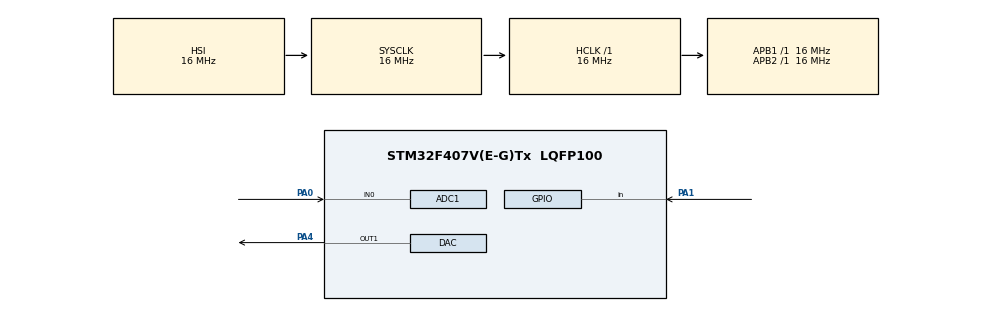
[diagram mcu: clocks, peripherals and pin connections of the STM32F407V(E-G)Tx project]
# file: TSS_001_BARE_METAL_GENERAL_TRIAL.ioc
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Mcu.Family=STM32F4
SH.COMP_DAC1_group.0=DAC_OUT1,DAC_OUT1
Dma.ADC1.0.Instance=DMA2_Stream0
RCC.CortexFreq_Value=16000000
ADC1.Rank-0\#ChannelRegularConversion=1
ADC1.ContinuousConvMode=ENABLE
Dma.DAC1.1.PeriphInc=DMA_PINC_DISABLE
ProjectManager.StackSize=0x400
PA0-WKUP.Signal=ADCx_IN0
Dma.DAC1.1.MemInc=DMA_MINC_ENABLE
Dma.ADC1.0.PeriphDataAlignment=DMA_PDATAALIGN_BYTE
Dma.DAC1.1.Mode=DMA_CIRCULAR
ProjectManager.TargetToolchain=STM32CubeIDE
NVIC.DMA1_Stream5_IRQn=true\:0\:0\:false\:false\:true\:false\:true
Dma.ADC1.0.Mode=DMA_CIRCULAR
ADC1.Resolution=ADC_RESOLUTION_8B
Dma.ADC1.0.Priority=DMA_PRIORITY_LOW
Dma.ADC1.0.Direction=DMA_PERIPH_TO_MEMORY
NVIC.DMA2_Stream0_IRQn=true\:0\:0\:false\:false\:true\:false\:true
RCC.LSE_VALUE=32768
Dma.ADC1.0.MemDataAlignment=DMA_MDATAALIGN_BYTE
PA1.Signal=GPIO_Input
RCC.AHBFreq_Value=16000000
ADC1.Channel-0\#ChannelRegularConversion=ADC_CHANNEL_0
RCC.HSE_VALUE=25000000
ADC1.ScanConvMode=DISABLE
board=custom
RCC.VCOOutputFreq_Value=192000000
RCC.APB2Freq_Value=16000000
Dma.ADC1.0.PeriphInc=DMA_PINC_DISABLE
Dma.DAC1.1.PeriphDataAlignment=DMA_PDATAALIGN_HALFWORD
SH.ADCx_IN0.0=ADC1_IN0,IN0
Dma.DAC1.1.Priority=DMA_PRIORITY_LOW
ADC1.DMAContinuousRequests=ENABLE
Dma.DAC1.1.FIFOMode=DMA_FIFOMODE_DISABLE
Mcu.Name=STM32F407V(E-G)Tx
ADC1.SamplingTime-0\#ChannelRegularConversion=ADC_SAMPLETIME_480CYCLES
Dma.DAC1.1.Direction=DMA_MEMORY_TO_PERIPH
PA4.Signal=COMP_DAC1_group
RCC.SYSCLKFreq_VALUE=16000000
Mcu.Package=LQFP100
ADC1.master=1
Dma.DAC1.1.Instance=DMA1_Stream5
Dma.ADC1.0.MemInc=DMA_MINC_ENABLE
ProjectManager.HeapSize=0x200
RCC.HSI_VALUE=16000000
NVIC.PriorityGroup=NVIC_PRIORITYGROUP_4
ADC1.NbrOfConversionFlag=1
Dma.Request1=DAC1
Dma.ADC1.0.FIFOMode=DMA_FIFOMODE_DISABLE
RCC.APB1Freq_Value=16000000
Dma.Request0=ADC1
Dma.DAC1.1.MemDataAlignment=DMA_MDATAALIGN_HALFWORD

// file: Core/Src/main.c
/* USER CODE BEGIN Header */
/**
  ******************************************************************************
  * @file           : main.c
  * @brief          : Main program body
  ******************************************************************************
  * @attention
  *
  * <h2><center>&copy; Copyright (c) 2022 STMicroelectronics.
  * All rights reserved.</center></h2>
  *
  * This software component is licensed by ST under BSD 3-Clause license,
  * the "License"; You may not use this file except in compliance with the
  * License. You may obtain a copy of the License at:
  *                        opensource.org/licenses/BSD-3-Clause
  *
  ******************************************************************************
  */
/* USER CODE END Header */
#include "main.h"

ADC_HandleTypeDef hadc1;
DMA_HandleTypeDef hdma_adc1;

DAC_HandleTypeDef hdac;
DMA_HandleTypeDef hdma_dac1;

void SystemClock_Config(void);
static void MX_GPIO_Init(void);
static void MX_DMA_Init(void);
static void MX_ADC1_Init(void);
static void MX_DAC_Init(void);

/* USER CODE BEGIN 0 */
uint8_t ButtonCount = 0 ;
uint8_t AdcValue8Bits ;

/*__weak void HAL_ADC_ConvHalfCpltCallback(ADC_HandleTypeDef* hadc) */

/**
  * ADC and DAC - DMA SETTINGS
  * DMA REQUEST SETTINGS :
  * MODE -> CIRCULAR MODE
  * DATA WIDTH   -> BYTE
  * BYTE         -> 8-BIT
  * HALF WORD    -> 16-BIT
  * WORD         -> 32-BIT
  * DOUBLE WORD  -> 64-BIT
  */

/* USER CODE END 0 */

int main(void)
{

  /* MCU Configuration--------------------------------------------------------*/

  /* Reset of all peripherals, Initializes the Flash interface and the Systick. */
  HAL_Init();

  /* Configure the system clock */
  SystemClock_Config();

  /* Initialize all configured peripherals */
  MX_GPIO_Init();
  MX_DMA_Init();
  MX_ADC1_Init();
  MX_DAC_Init();
  /* USER CODE BEGIN 2 */
  HAL_ADC_Start_DMA(&hadc1, (uint32_t *)&AdcValue8Bits, 1);
  HAL_DAC_Start_DMA(&hdac, DAC_CHANNEL_1, (uint32_t *)&AdcValue8Bits, 1, DAC_ALIGN_8B_R);
  /* USER CODE END 2 */

  /* Infinite loop */
  while (1)
  {

    /* USER CODE BEGIN 3 */
	  if(HAL_GPIO_ReadPin(GPIOA, GPIO_PIN_1))
	  {
		  while(HAL_GPIO_ReadPin(GPIOA, GPIO_PIN_1));
		  HAL_Delay(50);
		  ButtonCount++ ;
	  }
	  DacValue8Bits = AdcValue8Bits ;
	  HAL_DAC_SetValue(&hdac, DAC1_CHANNEL_1, DAC_ALIGN_8B_R, AdcValue8Bits);
  }
  /* USER CODE END 3 */
}

void SystemClock_Config(void)
{
  RCC_OscInitTypeDef RCC_OscInitStruct = {0};
  RCC_ClkInitTypeDef RCC_ClkInitStruct = {0};

  /** Configure the main internal regulator output voltage
  */
  __HAL_RCC_PWR_CLK_ENABLE();
  __HAL_PWR_VOLTAGESCALING_CONFIG(PWR_REGULATOR_VOLTAGE_SCALE1);
  /** Initializes the RCC Oscillators according to the specified parameters
  * in the RCC_OscInitTypeDef structure.
  */
  RCC_OscInitStruct.OscillatorType = RCC_OSCILLATORTYPE_HSI;
  RCC_OscInitStruct.HSIState = RCC_HSI_ON;
  RCC_OscInitStruct.HSICalibrationValue = RCC_HSICALIBRATION_DEFAULT;
  RCC_OscInitStruct.PLL.PLLState = RCC_PLL_NONE;
  if (HAL_RCC_OscConfig(&RCC_OscInitStruct) != HAL_OK)
  {
    Error_Handler();
  }
  /** Initializes the CPU, AHB and APB buses clocks
  */
  RCC_ClkInitStruct.ClockType = RCC_CLOCKTYPE_HCLK|RCC_CLOCKTYPE_SYSCLK
                              |RCC_CLOCKTYPE_PCLK1|RCC_CLOCKTYPE_PCLK2;
  RCC_ClkInitStruct.SYSCLKSource = RCC_SYSCLKSOURCE_HSI;
  RCC_ClkInitStruct.AHBCLKDivider = RCC_SYSCLK_DIV1;
  RCC_ClkInitStruct.APB1CLKDivider = RCC_HCLK_DIV1;
  RCC_ClkInitStruct.APB2CLKDivider = RCC_HCLK_DIV1;

  if (HAL_RCC_ClockConfig(&RCC_ClkInitStruct, FLASH_LATENCY_0) != HAL_OK)
  {
    Error_Handler();
  }
}

static void MX_ADC1_Init(void)
{

  ADC_ChannelConfTypeDef sConfig = {0};

  /** Configure the global features of the ADC (Clock, Resolution, Data Alignment and number of conversion)
  */
  hadc1.Instance = ADC1;
  hadc1.Init.ClockPrescaler = ADC_CLOCK_SYNC_PCLK_DIV2;
  hadc1.Init.Resolution = ADC_RESOLUTION_8B;
  hadc1.Init.ScanConvMode = DISABLE;
  hadc1.Init.ContinuousConvMode = ENABLE;
  hadc1.Init.DiscontinuousConvMode = DISABLE;
  hadc1.Init.ExternalTrigConvEdge = ADC_EXTERNALTRIGCONVEDGE_NONE;
  hadc1.Init.ExternalTrigConv = ADC_SOFTWARE_START;
  hadc1.Init.DataAlign = ADC_DATAALIGN_RIGHT;
  hadc1.Init.NbrOfConversion = 1;
  hadc1.Init.DMAContinuousRequests = ENABLE;
  hadc1.Init.EOCSelection = ADC_EOC_SINGLE_CONV;
  if (HAL_ADC_Init(&hadc1) != HAL_OK)
  {
    Error_Handler();
  }
  /** Configure for the selected ADC regular channel its corresponding rank in the sequencer and its sample time.
  */
  sConfig.Channel = ADC_CHANNEL_0;
  sConfig.Rank = 1;
  sConfig.SamplingTime = ADC_SAMPLETIME_480CYCLES;
  if (HAL_ADC_ConfigChannel(&hadc1, &sConfig) != HAL_OK)
  {
    Error_Handler();
  }

}

static void MX_DAC_Init(void)
{

  DAC_ChannelConfTypeDef sConfig = {0};

  /** DAC Initialization
  */
  hdac.Instance = DAC;
  if (HAL_DAC_Init(&hdac) != HAL_OK)
  {
    Error_Handler();
  }
  /** DAC channel OUT1 config
  */
  sConfig.DAC_Trigger = DAC_TRIGGER_NONE;
  sConfig.DAC_OutputBuffer = DAC_OUTPUTBUFFER_ENABLE;
  if (HAL_DAC_ConfigChannel(&hdac, &sConfig, DAC_CHANNEL_1) != HAL_OK)
  {
    Error_Handler();
  }

}

static void MX_DMA_Init(void)
{

  /* DMA controller clock enable */
  __HAL_RCC_DMA2_CLK_ENABLE();
  __HAL_RCC_DMA1_CLK_ENABLE();

  /* DMA interrupt init */
  /* DMA1_Stream5_IRQn interrupt configuration */
  HAL_NVIC_SetPriority(DMA1_Stream5_IRQn, 0, 0);
  HAL_NVIC_EnableIRQ(DMA1_Stream5_IRQn);
  /* DMA2_Stream0_IRQn interrupt configuration */
  HAL_NVIC_SetPriority(DMA2_Stream0_IRQn, 0, 0);
  HAL_NVIC_EnableIRQ(DMA2_Stream0_IRQn);

}

static void MX_GPIO_Init(void)
{
  GPIO_InitTypeDef GPIO_InitStruct = {0};

  /* GPIO Ports Clock Enable */
  __HAL_RCC_GPIOA_CLK_ENABLE();

  /*Configure GPIO pin : PA1 */
  GPIO_InitStruct.Pin = GPIO_PIN_1;
  GPIO_InitStruct.Mode = GPIO_MODE_INPUT;
  GPIO_InitStruct.Pull = GPIO_NOPULL;
  HAL_GPIO_Init(GPIOA, &GPIO_InitStruct);

}

void Error_Handler(void)
{
  __disable_irq();
  while (1)
  {
  }
}

/************************ (C) COPYRIGHT STMicroelectronics *****END OF FILE****/
